AUTOSAR XML (schema 00045)
package /Fcu
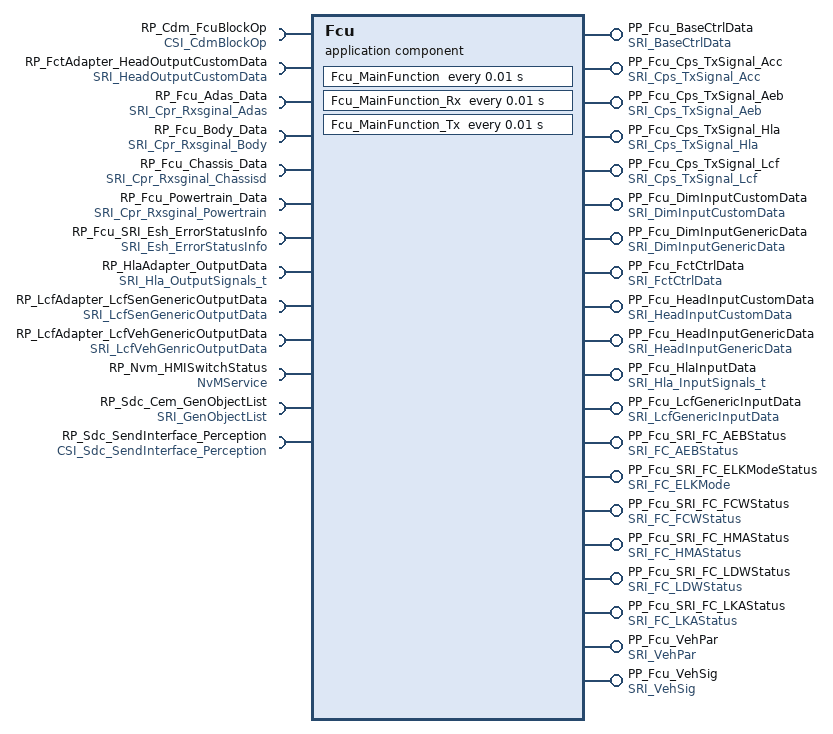
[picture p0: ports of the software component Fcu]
  application sw component type Fcu  # Functional Control Unit/Functional Conversion Unit
    20 x provide port:
      PP_Fcu_BaseCtrlData: provided-interface=SRI_BaseCtrlData
      PP_Fcu_Cps_TxSignal_Acc: provided-interface=SRI_Cps_TxSignal_Acc
      PP_Fcu_Cps_TxSignal_Aeb: provided-interface=SRI_Cps_TxSignal_Aeb
      PP_Fcu_Cps_TxSignal_Hla: provided-interface=SRI_Cps_TxSignal_Hla
      PP_Fcu_Cps_TxSignal_Lcf: provided-interface=SRI_Cps_TxSignal_Lcf
      PP_Fcu_DimInputCustomData: provided-interface=SRI_DimInputCustomData
      PP_Fcu_DimInputGenericData: provided-interface=SRI_DimInputGenericData
      PP_Fcu_FctCtrlData: provided-interface=SRI_FctCtrlData
      PP_Fcu_HeadInputCustomData: provided-interface=SRI_HeadInputCustomData
      PP_Fcu_HeadInputGenericData: provided-interface=SRI_HeadInputGenericData
      PP_Fcu_HlaInputData: provided-interface=SRI_Hla_InputSignals_t
      PP_Fcu_LcfGenericInputData: provided-interface=SRI_LcfGenericInputData
      PP_Fcu_SRI_FC_AEBStatus: provided-interface=SRI_FC_AEBStatus
      PP_Fcu_SRI_FC_ELKModeStatus: provided-interface=SRI_FC_ELKMode
      PP_Fcu_SRI_FC_FCWStatus: provided-interface=SRI_FC_FCWStatus
      PP_Fcu_SRI_FC_HMAStatus: provided-interface=SRI_FC_HMAStatus
      PP_Fcu_SRI_FC_LDWStatus: provided-interface=SRI_FC_LDWStatus
      PP_Fcu_SRI_FC_LKAStatus: provided-interface=SRI_FC_LKAStatus
      PP_Fcu_VehPar: provided-interface=SRI_VehPar
      PP_Fcu_VehSig: provided-interface=SRI_VehSig
    13 x require port:
      RP_Cdm_FcuBlockOp: required-interface=CSI_CdmBlockOp
      RP_FctAdapter_HeadOutputCustomData: required-interface=SRI_HeadOutputCustomData
      RP_Fcu_Adas_Data: required-interface=SRI_Cpr_Rxsginal_Adas
      RP_Fcu_Body_Data: required-interface=SRI_Cpr_Rxsginal_Body
      RP_Fcu_Chassis_Data: required-interface=SRI_Cpr_Rxsginal_Chassisd
      RP_Fcu_Powertrain_Data: required-interface=SRI_Cpr_Rxsginal_Powertrain
      RP_Fcu_SRI_Esh_ErrorStatusInfo: required-interface=SRI_Esh_ErrorStatusInfo
      RP_HlaAdapter_OutputData: required-interface=SRI_Hla_OutputSignals_t
      RP_LcfAdapter_LcfSenGenericOutputData: required-interface=SRI_LcfSenGenericOutputData
      RP_LcfAdapter_LcfVehGenericOutputData: required-interface=SRI_LcfVehGenricOutputData
      RP_Nvm_HMISwitchStatus: required-interface=NvMService
      RP_Sdc_Cem_GenObjectList: required-interface=SRI_GenObjectList
      RP_Sdc_SendInterface_Perception: required-interface=CSI_Sdc_SendInterface_Perception
    behavior Fcu_IB: handle-termination-and-restart=NO-SUPPORT
      init event InitEvent_Fcu_InitFunction: start-on-event=Fcu_InitFunction
      timing event TimingEvent_Fcu_MainFunction: start-on-event=Fcu_MainFunction, period=0.01
      timing event TimingEvent_Fcu_MainFunction_Rx: start-on-event=Fcu_MainFunction_Rx, period=0.01
      timing event TimingEvent_Fcu_MainFunction_Tx: start-on-event=Fcu_MainFunction_Tx, period=0.01
      4 x runnable:
        Fcu_InitFunction
          data-receive-point-by-arguments:
            4 x access:
              drparg_GenObjectList: accessed-variable=RP_Sdc_Cem_GenObjectList.GenObjectList
              drparg_HeadOutputCustomData: accessed-variable=RP_FctAdapter_HeadOutputCustomData.HeadOutputCustomData
              drparg_LcfSenGenericOutputDa: accessed-variable=RP_LcfAdapter_LcfSenGenericOutputData.LcfSenGenericOutputData
              drparg_LcfVehGenericOutputDa: accessed-variable=RP_LcfAdapter_LcfVehGenericOutputData.LcfVehGenricOutputData
          data-send-points:
            9 x access:
              dsp_BaseCtrlData: accessed-variable=PP_Fcu_BaseCtrlData.BaseCtrlData
              dsp_DimInputCustomData: accessed-variable=PP_Fcu_DimInputCustomData.DimInputCustomData
              dsp_DimInputGenericData: accessed-variable=PP_Fcu_DimInputGenericData.DimInputGenericData
              dsp_FctCtrlData: accessed-variable=PP_Fcu_FctCtrlData.FctCtrlData
              dsp_HeadInputCustomData: accessed-variable=PP_Fcu_HeadInputCustomData.HeadInputCustomData
              dsp_HeadInputGenericData: accessed-variable=PP_Fcu_HeadInputGenericData.HeadInputGenericData
              dsp_LcfGenericInputData: accessed-variable=PP_Fcu_LcfGenericInputData.LcfGenericInputData
              dsp_VehPar: accessed-variable=PP_Fcu_VehPar.VehPar
              dsp_VehSig: accessed-variable=PP_Fcu_VehSig.VehSig
        Fcu_MainFunction
          data-receive-point-by-arguments:
            258 x access:
              drparg_ACCMode: accessed-variable=RP_Fcu_Adas_Data.ACCMode
              drparg_ACCMode_Status: accessed-variable=RP_Fcu_Adas_Data.ACCMode_Status
              drparg_ACC_HostLaneLeftStatus: accessed-variable=RP_Fcu_Body_Data.ACC_HostLaneLeftStatus
              drparg_ACC_HostLaneRightStat: accessed-variable=RP_Fcu_Body_Data.ACC_HostLaneRightStatus
              drparg_ACC_IACCHWAMode: accessed-variable=RP_Fcu_Body_Data.AccIaccHWAMode
              drparg_AccIaccHWAMode_Status: accessed-variable=RP_Fcu_Body_Data.AccIaccHWAMode_Status
              drparg_AdsUDLCStatus: accessed-variable=RP_Fcu_Chassis_Data.AdsUDLCStatus
              drparg_AdsUDLCStatus_Status: accessed-variable=RP_Fcu_Chassis_Data.AdsUDLCStatus_Status
              drparg_BCM_BrakeLampError: accessed-variable=RP_Fcu_Body_Data.BCM_BrakeLampError
              drparg_BCM_BrakeLampError_St: accessed-variable=RP_Fcu_Body_Data.BCM_BrakeLampError_Status
              drparg_BCM_TurnLightSwitchSt: accessed-variable=RP_Fcu_Body_Data.BCM_TurnLightSwitchSts_Status
              drparg_BCM_TurnLightSwitchSts: accessed-variable=RP_Fcu_Body_Data.BCM_TurnLightSwitchSts
              drparg_BcmAutHeadLiSts: accessed-variable=RP_Fcu_Body_Data.BcmAutHeadLiSts
              drparg_BcmAutHeadLiSts_Status: accessed-variable=RP_Fcu_Body_Data.BcmAutHeadLiSts_Status
              drparg_BcmDrvrDoorSts: accessed-variable=RP_Fcu_Body_Data.BcmDrvrDoorSts
              drparg_BcmDrvrDoorSts_Status: accessed-variable=RP_Fcu_Body_Data.BcmDrvrDoorSts_Status
              drparg_BcmEmgyLiSts: accessed-variable=RP_Fcu_Body_Data.BcmEmgyLiSts
              drparg_BcmEmgyLiSts_Status: accessed-variable=RP_Fcu_Body_Data.BcmEmgyLiSts_Status
              drparg_BcmFrntFogLmpSts: accessed-variable=RP_Fcu_Body_Data.BcmFrntFogLmpSts
              drparg_BcmFrntFogLmpSts_Stat: accessed-variable=RP_Fcu_Body_Data.BcmFrntFogLmpSts_Status
              drparg_BcmFrntWiperSts: accessed-variable=RP_Fcu_Body_Data.BcmFrntWiperSts
              drparg_BcmFrntWiperSts_Status: accessed-variable=RP_Fcu_Body_Data.BcmFrntWiperSts_Status
              drparg_BcmHiBeamSts: accessed-variable=RP_Fcu_Body_Data.BcmHiBeamSts
              drparg_BcmHiBeamSts_Status: accessed-variable=RP_Fcu_Body_Data.BcmHiBeamSts_Status
              drparg_BcmLeReDoorSts: accessed-variable=RP_Fcu_Body_Data.BcmLeReDoorSts
              drparg_BcmLeReDoorSts_Status: accessed-variable=RP_Fcu_Body_Data.BcmLeReDoorSts_Status
              drparg_BcmLoBeamSts: accessed-variable=RP_Fcu_Body_Data.BcmLoBeamSts
              drparg_BcmLoBeamSts_Status: accessed-variable=RP_Fcu_Body_Data.BcmLoBeamSts_Status
              drparg_BcmPassDoorSts: accessed-variable=RP_Fcu_Body_Data.BcmPassDoorSts
              drparg_BcmPassDoorSts_Status: accessed-variable=RP_Fcu_Body_Data.BcmPassDoorSts_Status
              drparg_BcmReFoglmpSts: accessed-variable=RP_Fcu_Body_Data.BcmReFoglmpSts
              drparg_BcmReFoglmpSts_Status: accessed-variable=RP_Fcu_Body_Data.BcmReFoglmpSts_Status
              drparg_BcmRiReDoorSts: accessed-variable=RP_Fcu_Body_Data.BcmRiReDoorSts
              drparg_BcmRiReDoorSts_Status: accessed-variable=RP_Fcu_Body_Data.BcmRiReDoorSts_Status
              drparg_BcmTurnIndcrLe: accessed-variable=RP_Fcu_Body_Data.BcmTurnIndcrLe
              drparg_BcmTurnIndcrLe_Status: accessed-variable=RP_Fcu_Body_Data.BcmTurnIndcrLe_Status
              drparg_BcmTurnIndcrRi: accessed-variable=RP_Fcu_Body_Data.BcmTurnIndcrRi
              drparg_BcmTurnIndcrRi_Status: accessed-variable=RP_Fcu_Body_Data.BcmTurnIndcrRi_Status
              drparg_BrakePressureSimulato: accessed-variable=RP_Fcu_Chassis_Data.BrakePressureSimulator_Status
              drparg_BrakePressureSimulator: accessed-variable=RP_Fcu_Chassis_Data.BrakePressureSimulator
              drparg_DE_Esh_ErrorStatusInfo: accessed-variable=RP_Fcu_SRI_Esh_ErrorStatusInfo.DE_Esh_ErrorStatusInfo
              drparg_EPS_APA_EpasFAILED: accessed-variable=RP_Fcu_Chassis_Data.EPS_APA_EpasFAILED
              drparg_EPS_APA_EpasFAILED_St: accessed-variable=RP_Fcu_Chassis_Data.EPS_APA_EpasFAILED_Status
              drparg_EPS_ActualMotorTorq: accessed-variable=RP_Fcu_Chassis_Data.EPS_ActualMotorTorq
              drparg_EPS_ActualMotorTorq_S: accessed-variable=RP_Fcu_Chassis_Data.EPS_ActualMotorTorq_Status
              drparg_EPS_ActualTorsionBarT: accessed-variable=RP_Fcu_Chassis_Data.EPS_ActualTorsionBarTorq
              drparg_EPS_ActualTorsionBarT0: accessed-variable=RP_Fcu_Chassis_Data.EPS_ActualTorsionBarTorq_Status
              drparg_EPS_MeasuredTorsionBa: accessed-variable=RP_Fcu_Chassis_Data.EPS_MeasuredTorsionBarTorqValid
              drparg_EPS_Pinionang_Vali: accessed-variable=RP_Fcu_Chassis_Data.EPS_Pinionang_Valid
              drparg_EPS_fault_state: accessed-variable=RP_Fcu_Chassis_Data.EPS_fault_state
              drparg_EPS_fault_state_Status: accessed-variable=RP_Fcu_Chassis_Data.EPS_fault_state_Status
              drparg_ESP_LatAccelValid: accessed-variable=RP_Fcu_Chassis_Data.ESP_LatAccelValid
              drparg_ESP_LongAccelValid: accessed-variable=RP_Fcu_Chassis_Data.ESP_LongAccelValid
              drparg_ESP_YawRateValid: accessed-variable=RP_Fcu_Chassis_Data.ESP_YawRateValid
              drparg_EpsConcussAvailabilit: accessed-variable=RP_Fcu_Chassis_Data.EpsConcussAvailabilityStatus
              drparg_EpsConcussAvailabilit0: accessed-variable=RP_Fcu_Chassis_Data.EpsConcussAvailabilityStatus_Status
              drparg_EpsFaild: accessed-variable=RP_Fcu_Chassis_Data.EpsFaild
              drparg_EpsFaild_Status: accessed-variable=RP_Fcu_Chassis_Data.EpsFaild_Status
              drparg_EpsIACCabortreason: accessed-variable=RP_Fcu_Chassis_Data.EpsIACCabortreason
              drparg_EpsIACCabortreason_St: accessed-variable=RP_Fcu_Chassis_Data.EpsIACCabortreason_Status
              drparg_EpsLatCtrlActive: accessed-variable=RP_Fcu_Chassis_Data.EpsLatCtrlActive
              drparg_EpsLatCtrlActive_Stat: accessed-variable=RP_Fcu_Chassis_Data.EpsLatCtrlActive_Status
              drparg_EpsLatCtrlAvailabilit: accessed-variable=RP_Fcu_Chassis_Data.EpsLatCtrlAvailabilityStatus
              drparg_EpsLatCtrlAvailabilit0: accessed-variable=RP_Fcu_Chassis_Data.EpsLatCtrlAvailabilityStatus_Status
              drparg_EpsMeasuredTorsionBar: accessed-variable=RP_Fcu_Chassis_Data.EpsMeasuredTorsionBarTorque
              drparg_EpsMeasuredTorsionBar0: accessed-variable=RP_Fcu_Chassis_Data.EpsMeasuredTorsionBarTorq_Status
              drparg_EpsMeasuredTorsionBar1: accessed-variable=RP_Fcu_Chassis_Data.EpsMeasuredTorsionBarTorque_Status
              drparg_EpsPinionang: accessed-variable=RP_Fcu_Chassis_Data.EpsPinionang
              drparg_EpsPinionang_Status: accessed-variable=RP_Fcu_Chassis_Data.EpsPinionang_Status
              drparg_EpsSasCalSts: accessed-variable=RP_Fcu_Chassis_Data.EpsSasCalSts
              drparg_EpsSasCalSts_Status: accessed-variable=RP_Fcu_Chassis_Data.EpsSasCalSts_Status
              drparg_EpsSasSteerAg: accessed-variable=RP_Fcu_Chassis_Data.EpsSasSteerAg
              drparg_EpsSasSteerAgVld: accessed-variable=RP_Fcu_Chassis_Data.EpsSasSteerAgVld
              drparg_EpsSasSteerAg_Status: accessed-variable=RP_Fcu_Chassis_Data.EpsSasSteerAg_Status
              drparg_EpsSteerAgRate: accessed-variable=RP_Fcu_Chassis_Data.EpsSteerAgRate
              drparg_EpsSteerAgRate_Status: accessed-variable=RP_Fcu_Chassis_Data.EpsSteerAgRate_Status
              drparg_EpsSteerAgSensFilr: accessed-variable=RP_Fcu_Chassis_Data.EpsSteerAgSensFilr
              drparg_EpsSteerAgSensFilr_St: accessed-variable=RP_Fcu_Chassis_Data.EpsSteerAgSensFilr_Status
              drparg_EspABAactive: accessed-variable=RP_Fcu_Chassis_Data.EspABAactive
              drparg_EspABAactive_Status: accessed-variable=RP_Fcu_Chassis_Data.EspABAactive_Status
              drparg_EspABAavailable: accessed-variable=RP_Fcu_Chassis_Data.EspABAavailable
              drparg_EspABAavailable_Status: accessed-variable=RP_Fcu_Chassis_Data.EspABAavailable_Status
              drparg_EspAEBAvailable: accessed-variable=RP_Fcu_Chassis_Data.EspAEBAvailable
              drparg_EspAEBAvailable_Status: accessed-variable=RP_Fcu_Chassis_Data.EspAEBAvailable_Status
              drparg_EspAEBdecActive: accessed-variable=RP_Fcu_Chassis_Data.EspAEBdecActive
              drparg_EspAEBdecActive_Status: accessed-variable=RP_Fcu_Chassis_Data.EspAEBdecActive_Status
              drparg_EspAWBactive: accessed-variable=RP_Fcu_Chassis_Data.EspAWBactive
              drparg_EspAWBactive_Status: accessed-variable=RP_Fcu_Chassis_Data.EspAWBactive_Status
              drparg_EspAWBavailable: accessed-variable=RP_Fcu_Chassis_Data.EspAWBavailable
              drparg_EspAWBavailable_Status: accessed-variable=RP_Fcu_Chassis_Data.EspAWBavailable_Status
              drparg_EspAbsActv: accessed-variable=RP_Fcu_Chassis_Data.EspAbsActv
              drparg_EspAbsActv_Status: accessed-variable=RP_Fcu_Chassis_Data.EspAbsActv_Status
              drparg_EspAbsFailr: accessed-variable=RP_Fcu_Chassis_Data.EspAbsFailr
              drparg_EspAbsFailr_Status: accessed-variable=RP_Fcu_Chassis_Data.EspAbsFailr_Status
              drparg_EspActvSts: accessed-variable=RP_Fcu_Chassis_Data.EspActvSts
              drparg_EspActvSts_Status: accessed-variable=RP_Fcu_Chassis_Data.EspActvSts_Status
              drparg_EspEbdFailr: accessed-variable=RP_Fcu_Chassis_Data.EspEbdFailr
              drparg_EspEbdFailr_Status: accessed-variable=RP_Fcu_Chassis_Data.EspEbdFailr_Status
              drparg_EspLatAccel: accessed-variable=RP_Fcu_Chassis_Data.EspLatAccel
              drparg_EspLatAccel_Status: accessed-variable=RP_Fcu_Chassis_Data.EspLatAccel_Status
              drparg_EspLongAccel: accessed-variable=RP_Fcu_Chassis_Data.EspLongAccel
              drparg_EspLongAccel_Status: accessed-variable=RP_Fcu_Chassis_Data.EspLongAccel_Status
              drparg_EspPrefillActive: accessed-variable=RP_Fcu_Chassis_Data.EspPrefillActive
              drparg_EspPrefillActive_Stat: accessed-variable=RP_Fcu_Chassis_Data.EspPrefillActive_Status
              drparg_EspPrefillAvailable: accessed-variable=RP_Fcu_Chassis_Data.EspPrefillAvailable
              drparg_EspPrefillAvailable_S: accessed-variable=RP_Fcu_Chassis_Data.EspPrefillAvailable_Status
              drparg_EspTcsActvSts: accessed-variable=RP_Fcu_Chassis_Data.EspTcsActvSts
              drparg_EspTcsActvSts_Status: accessed-variable=RP_Fcu_Chassis_Data.EspTcsActvSts_Status
              drparg_EspTcsFailr: accessed-variable=RP_Fcu_Chassis_Data.EspTcsFailr
              drparg_EspTcsFailr_Status: accessed-variable=RP_Fcu_Chassis_Data.EspTcsFailr_Status
              drparg_EspVdcActvSts: accessed-variable=RP_Fcu_Chassis_Data.EspVdcActvSts
              drparg_EspVdcActvSts_Status: accessed-variable=RP_Fcu_Chassis_Data.EspVdcActvSts_Status
              drparg_EspVehSpd: accessed-variable=RP_Fcu_Chassis_Data.EspVehSpd
              drparg_EspVehSpdVld: accessed-variable=RP_Fcu_Chassis_Data.EspVehSpdVld
              drparg_EspVehSpd_Status: accessed-variable=RP_Fcu_Chassis_Data.EspVehSpd_Status
              drparg_EspYawRate: accessed-variable=RP_Fcu_Chassis_Data.EspYawRate
              drparg_EspYawRate_Status: accessed-variable=RP_Fcu_Chassis_Data.EspYawRate_Status
              drparg_FR_RadarFailureStatus: accessed-variable=RP_Fcu_Adas_Data.FR_RadarFailureStatus
              drparg_FR_RadarFailureStatus0: accessed-variable=RP_Fcu_Adas_Data.FR_RadarFailureStatus_Status
              drparg_FRadarCalibrationStat: accessed-variable=RP_Fcu_Adas_Data.FRadarCalibrationStatus
              drparg_FRadarCalibrationStat0: accessed-variable=RP_Fcu_Adas_Data.FRadarCalibrationStatus_Status
              drparg_GenObjectList: accessed-variable=RP_Sdc_Cem_GenObjectList.GenObjectList
              drparg_HeadOutputCustomData: accessed-variable=RP_FctAdapter_HeadOutputCustomData.HeadOutputCustomData
              drparg_Hla_OutputSignals_t: accessed-variable=RP_HlaAdapter_OutputData.Hla_OutputSignals_t
              drparg_IBCU_PFSBrakePressure: accessed-variable=RP_Fcu_Chassis_Data.IBCU_PFSBrakePressureValid
              drparg_IP_DISFail: accessed-variable=RP_Fcu_Body_Data.IP_DISFail
              drparg_IP_DISFail_Status: accessed-variable=RP_Fcu_Body_Data.IP_DISFail_Status
              drparg_IP_QDashACCFail: accessed-variable=RP_Fcu_Body_Data.IP_QDashACCFail
              drparg_IP_QDashACCFail_Status: accessed-variable=RP_Fcu_Body_Data.IP_QDashACCFail_Status
              drparg_IbBrkPedlStsGb: accessed-variable=RP_Fcu_Chassis_Data.IbBrkPedlStsGb
              drparg_IbBrkPedlStsGbVld: accessed-variable=RP_Fcu_Chassis_Data.IbBrkPedlStsGbVld
              drparg_IbBrkPedlStsGb_Status: accessed-variable=RP_Fcu_Chassis_Data.IbBrkPedlStsGb_Status
              drparg_IbBrkPedlTrvlDrvr: accessed-variable=RP_Fcu_Chassis_Data.IbBrkPedlTrvlDrvr
              drparg_IbBrkPedlTrvlDrvrVld: accessed-variable=RP_Fcu_Chassis_Data.IbBrkPedlTrvlDrvrVld
              drparg_LcfSenGenericOutputDa: accessed-variable=RP_LcfAdapter_LcfSenGenericOutputData.LcfSenGenericOutputData
              drparg_LcfVehGenericOutputDa: accessed-variable=RP_LcfAdapter_LcfVehGenericOutputData.LcfVehGenricOutputData
              drparg_PlungerBrakePressure: accessed-variable=RP_Fcu_Chassis_Data.PlungerBrakePressure
              drparg_PlungerBrakePressure_: accessed-variable=RP_Fcu_Chassis_Data.PlungerBrakePressure_Status
              drparg_RadarObj1_Dx: accessed-variable=RP_Fcu_Adas_Data.RadarObj1_Dx
              drparg_RadarObj1_Dx_Status: accessed-variable=RP_Fcu_Adas_Data.RadarObj1_Dx_Status
              drparg_RadarObj1_Dy: accessed-variable=RP_Fcu_Adas_Data.RadarObj1_Dy
              drparg_RadarObj1_Dy_Status: accessed-variable=RP_Fcu_Adas_Data.RadarObj1_Dy_Status
              drparg_RadarObj1_ExistProb: accessed-variable=RP_Fcu_Adas_Data.RadarObj1_ExistProb
              drparg_RadarObj1_ExistProb_S: accessed-variable=RP_Fcu_Adas_Data.RadarObj1_ExistProb_Status
              drparg_RadarObj1_Length: accessed-variable=RP_Fcu_Adas_Data.RadarObj1_Length
              drparg_RadarObj1_Length_Stat: accessed-variable=RP_Fcu_Adas_Data.RadarObj1_Length_Status
              drparg_RadarObj1_Location: accessed-variable=RP_Fcu_Adas_Data.RadarObj1_Location
              drparg_RadarObj1_Location_St: accessed-variable=RP_Fcu_Adas_Data.RadarObj1_Location_Status
              drparg_RadarObj1_Measured: accessed-variable=RP_Fcu_Adas_Data.RadarObj1_Measured
              drparg_RadarObj1_Measured_St: accessed-variable=RP_Fcu_Adas_Data.RadarObj1_Measured_Status
              drparg_RadarObj1_RelAx: accessed-variable=RP_Fcu_Adas_Data.RadarObj1_RelAx
              drparg_RadarObj1_RelAx_Status: accessed-variable=RP_Fcu_Adas_Data.RadarObj1_RelAx_Status
              drparg_RadarObj1_RelVx: accessed-variable=RP_Fcu_Adas_Data.RadarObj1_RelVx
              drparg_RadarObj1_RelVx_Status: accessed-variable=RP_Fcu_Adas_Data.RadarObj1_RelVx_Status
              drparg_RadarObj1_RelVy: accessed-variable=RP_Fcu_Adas_Data.RadarObj1_RelVy
              drparg_RadarObj1_RelVy_Status: accessed-variable=RP_Fcu_Adas_Data.RadarObj1_RelVy_Status
              drparg_RadarObj1_Width: accessed-variable=RP_Fcu_Adas_Data.RadarObj1_Width
              drparg_RadarObj1_Width_Status: accessed-variable=RP_Fcu_Adas_Data.RadarObj1_Width_Status
              drparg_RadarObj2_Dx: accessed-variable=RP_Fcu_Adas_Data.RadarObj2_Dx
              drparg_RadarObj2_Dx_Status: accessed-variable=RP_Fcu_Adas_Data.RadarObj2_Dx_Status
              drparg_RadarObj2_Dy: accessed-variable=RP_Fcu_Adas_Data.RadarObj2_Dy
              drparg_RadarObj2_Dy_Status: accessed-variable=RP_Fcu_Adas_Data.RadarObj2_Dy_Status
              drparg_RadarObj2_ExistProb: accessed-variable=RP_Fcu_Adas_Data.RadarObj2_ExistProb
              drparg_RadarObj2_ExistProb_S: accessed-variable=RP_Fcu_Adas_Data.RadarObj2_ExistProb_Status
              drparg_RadarObj2_Length: accessed-variable=RP_Fcu_Adas_Data.RadarObj2_Length
              drparg_RadarObj2_Length_Stat: accessed-variable=RP_Fcu_Adas_Data.RadarObj2_Length_Status
              drparg_RadarObj2_Location: accessed-variable=RP_Fcu_Adas_Data.RadarObj2_Location
              drparg_RadarObj2_Location_St: accessed-variable=RP_Fcu_Adas_Data.RadarObj2_Location_Status
              drparg_RadarObj2_Measured: accessed-variable=RP_Fcu_Adas_Data.RadarObj2_Measured
              drparg_RadarObj2_Measured_St: accessed-variable=RP_Fcu_Adas_Data.RadarObj2_Measured_Status
              drparg_RadarObj2_RelAx: accessed-variable=RP_Fcu_Adas_Data.RadarObj2_RelAx
              drparg_RadarObj2_RelAx_Status: accessed-variable=RP_Fcu_Adas_Data.RadarObj2_RelAx_Status
              drparg_RadarObj2_RelVx: accessed-variable=RP_Fcu_Adas_Data.RadarObj2_RelVx
              drparg_RadarObj2_RelVx_Status: accessed-variable=RP_Fcu_Adas_Data.RadarObj2_RelVx_Status
              drparg_RadarObj2_RelVy: accessed-variable=RP_Fcu_Adas_Data.RadarObj2_RelVy
              drparg_RadarObj2_RelVy_Status: accessed-variable=RP_Fcu_Adas_Data.RadarObj2_RelVy_Status
              drparg_RadarObj2_Width: accessed-variable=RP_Fcu_Adas_Data.RadarObj2_Width
              drparg_RadarObj2_Width_Status: accessed-variable=RP_Fcu_Adas_Data.RadarObj2_Width_Status
              drparg_RadarObj3_Dx: accessed-variable=RP_Fcu_Adas_Data.RadarObj3_Dx
              drparg_RadarObj3_Dx_Status: accessed-variable=RP_Fcu_Adas_Data.RadarObj3_Dx_Status
              drparg_RadarObj3_Dy: accessed-variable=RP_Fcu_Adas_Data.RadarObj3_Dy
              drparg_RadarObj3_Dy_Status: accessed-variable=RP_Fcu_Adas_Data.RadarObj3_Dy_Status
              drparg_RadarObj3_ExistProb: accessed-variable=RP_Fcu_Adas_Data.RadarObj3_ExistProb
              drparg_RadarObj3_ExistProb_S: accessed-variable=RP_Fcu_Adas_Data.RadarObj3_ExistProb_Status
              drparg_RadarObj3_Length: accessed-variable=RP_Fcu_Adas_Data.RadarObj3_Length
              drparg_RadarObj3_Length_Stat: accessed-variable=RP_Fcu_Adas_Data.RadarObj3_Length_Status
              drparg_RadarObj3_Location: accessed-variable=RP_Fcu_Adas_Data.RadarObj3_Location
              drparg_RadarObj3_Location_St: accessed-variable=RP_Fcu_Adas_Data.RadarObj3_Location_Status
              drparg_RadarObj3_Measured: accessed-variable=RP_Fcu_Adas_Data.RadarObj3_Measured
              drparg_RadarObj3_Measured_St: accessed-variable=RP_Fcu_Adas_Data.RadarObj3_Measured_Status
              drparg_RadarObj3_RelAx: accessed-variable=RP_Fcu_Adas_Data.RadarObj3_RelAx
              drparg_RadarObj3_RelAx_Status: accessed-variable=RP_Fcu_Adas_Data.RadarObj3_RelAx_Status
              drparg_RadarObj3_RelVx: accessed-variable=RP_Fcu_Adas_Data.RadarObj3_RelVx
              drparg_RadarObj3_RelVx_Status: accessed-variable=RP_Fcu_Adas_Data.RadarObj3_RelVx_Status
              drparg_RadarObj3_RelVy: accessed-variable=RP_Fcu_Adas_Data.RadarObj3_RelVy
              drparg_RadarObj3_RelVy_Status: accessed-variable=RP_Fcu_Adas_Data.RadarObj3_RelVy_Status
              drparg_RadarObj3_Width: accessed-variable=RP_Fcu_Adas_Data.RadarObj3_Width
              drparg_RadarObj3_Width_Status: accessed-variable=RP_Fcu_Adas_Data.RadarObj3_Width_Status
              drparg_RadarObj4_Dx: accessed-variable=RP_Fcu_Adas_Data.RadarObj4_Dx
              drparg_RadarObj4_Dx_Status: accessed-variable=RP_Fcu_Adas_Data.RadarObj4_Dx_Status
              drparg_RadarObj4_Dy: accessed-variable=RP_Fcu_Adas_Data.RadarObj4_Dy
              drparg_RadarObj4_Dy_Status: accessed-variable=RP_Fcu_Adas_Data.RadarObj4_Dy_Status
              drparg_RadarObj4_ExistProb: accessed-variable=RP_Fcu_Adas_Data.RadarObj4_ExistProb
              drparg_RadarObj4_ExistProb_S: accessed-variable=RP_Fcu_Adas_Data.RadarObj4_ExistProb_Status
              drparg_RadarObj4_Length: accessed-variable=RP_Fcu_Adas_Data.RadarObj4_Length
              drparg_RadarObj4_Length_Stat: accessed-variable=RP_Fcu_Adas_Data.RadarObj4_Length_Status
              drparg_RadarObj4_Location: accessed-variable=RP_Fcu_Adas_Data.RadarObj4_Location
              drparg_RadarObj4_Location_St: accessed-variable=RP_Fcu_Adas_Data.RadarObj4_Location_Status
              drparg_RadarObj4_Measured: accessed-variable=RP_Fcu_Adas_Data.RadarObj4_Measured
              drparg_RadarObj4_Measured_St: accessed-variable=RP_Fcu_Adas_Data.RadarObj4_Measured_Status
              drparg_RadarObj4_RelAx: accessed-variable=RP_Fcu_Adas_Data.RadarObj4_RelAx
              drparg_RadarObj4_RelAx_Status: accessed-variable=RP_Fcu_Adas_Data.RadarObj4_RelAx_Status
              drparg_RadarObj4_RelVx: accessed-variable=RP_Fcu_Adas_Data.RadarObj4_RelVx
              drparg_RadarObj4_RelVx_Status: accessed-variable=RP_Fcu_Adas_Data.RadarObj4_RelVx_Status
              drparg_RadarObj4_RelVy: accessed-variable=RP_Fcu_Adas_Data.RadarObj4_RelVy
              drparg_RadarObj4_RelVy_Status: accessed-variable=RP_Fcu_Adas_Data.RadarObj4_RelVy_Status
              drparg_RadarObj4_Width: accessed-variable=RP_Fcu_Adas_Data.RadarObj4_Width
              drparg_RadarObj4_Width_Status: accessed-variable=RP_Fcu_Adas_Data.RadarObj4_Width_Status
              drparg_SrsDrvrBucSwtSts: accessed-variable=RP_Fcu_Body_Data.SrsDrvrBucSwtSts
              drparg_SrsDrvrBucSwtSts_Stat: accessed-variable=RP_Fcu_Body_Data.SrsDrvrBucSwtSts_Status
              drparg_SrsPassBucSwtSts: accessed-variable=RP_Fcu_Body_Data.SrsPassBucSwtSts
              drparg_SrsPassBucSwtSts_Stat: accessed-variable=RP_Fcu_Body_Data.SrsPassBucSwtSts_Status
              drparg_TmsFrntBlowMod: accessed-variable=RP_Fcu_Body_Data.TmsFrntBlowMod
              drparg_TmsFrntBlowMod_Status: accessed-variable=RP_Fcu_Body_Data.TmsFrntBlowMod_Status
              drparg_VcuAccrPedlPosn: accessed-variable=RP_Fcu_Chassis_Data.VcuAccrPedlPosn
              drparg_VcuAccrPedlPosnVld: accessed-variable=RP_Fcu_Chassis_Data.VcuAccrPedlPosnVld
              drparg_VcuAccrPedlPosn_Status: accessed-variable=RP_Fcu_Chassis_Data.VcuAccrPedlPosn_Status
              drparg_VcuGearPosn: accessed-variable=RP_Fcu_Chassis_Data.VcuGearPosn
              drparg_VcuGearPosn_Status: accessed-variable=RP_Fcu_Chassis_Data.VcuGearPosn_Status
              drparg_VcuVehGearPosnVld: accessed-variable=RP_Fcu_Chassis_Data.VcuVehGearPosnVld
              drparg_WhlSpdFrntLePls: accessed-variable=RP_Fcu_Powertrain_Data.WhlSpdFrntLePls
              drparg_WhlSpdFrntLePls_Status: accessed-variable=RP_Fcu_Powertrain_Data.WhlSpdFrntLePls_Status
              drparg_WhlSpdFrntRiPls: accessed-variable=RP_Fcu_Powertrain_Data.WhlSpdFrntRiPls
              drparg_WhlSpdFrntRiPls_Status: accessed-variable=RP_Fcu_Powertrain_Data.WhlSpdFrntRiPls_Status
              drparg_WhlSpdLeFrntData: accessed-variable=RP_Fcu_Powertrain_Data.WhlSpdLeFrntData
              drparg_WhlSpdLeFrntDataVld: accessed-variable=RP_Fcu_Powertrain_Data.WhlSpdLeFrntDataVld
              drparg_WhlSpdLeFrntData_Stat: accessed-variable=RP_Fcu_Powertrain_Data.WhlSpdLeFrntData_Status
              drparg_WhlSpdLeFrntDir: accessed-variable=RP_Fcu_Powertrain_Data.WhlSpdLeFrntDir
              drparg_WhlSpdLeFrntDir_Status: accessed-variable=RP_Fcu_Powertrain_Data.WhlSpdLeFrntDir_Status
              drparg_WhlSpdLeReData: accessed-variable=RP_Fcu_Powertrain_Data.WhlSpdLeReData
              drparg_WhlSpdLeReDataVld: accessed-variable=RP_Fcu_Powertrain_Data.WhlSpdLeReDataVld
              drparg_WhlSpdLeReData_Status: accessed-variable=RP_Fcu_Powertrain_Data.WhlSpdLeReData_Status
              drparg_WhlSpdLeReDir: accessed-variable=RP_Fcu_Powertrain_Data.WhlSpdLeReDir
              drparg_WhlSpdLeReDir_Status: accessed-variable=RP_Fcu_Powertrain_Data.WhlSpdLeReDir_Status
              drparg_WhlSpdReLePls: accessed-variable=RP_Fcu_Powertrain_Data.WhlSpdReLePls
              drparg_WhlSpdReLePls_Status: accessed-variable=RP_Fcu_Powertrain_Data.WhlSpdReLePls_Status
              drparg_WhlSpdReRiPls: accessed-variable=RP_Fcu_Powertrain_Data.WhlSpdReRiPls
              drparg_WhlSpdReRiPls_Status: accessed-variable=RP_Fcu_Powertrain_Data.WhlSpdReRiPls_Status
              drparg_WhlSpdRiFrntData: accessed-variable=RP_Fcu_Powertrain_Data.WhlSpdRiFrntData
              drparg_WhlSpdRiFrntDataVld: accessed-variable=RP_Fcu_Powertrain_Data.WhlSpdRiFrntDataVld
              drparg_WhlSpdRiFrntData_Stat: accessed-variable=RP_Fcu_Powertrain_Data.WhlSpdRiFrntData_Status
              drparg_WhlSpdRiFrntDir: accessed-variable=RP_Fcu_Powertrain_Data.WhlSpdRiFrntDir
              drparg_WhlSpdRiFrntDir_Status: accessed-variable=RP_Fcu_Powertrain_Data.WhlSpdRiFrntDir_Status
              drparg_WhlSpdRiReData: accessed-variable=RP_Fcu_Powertrain_Data.WhlSpdRiReData
              drparg_WhlSpdRiReDataVld: accessed-variable=RP_Fcu_Powertrain_Data.WhlSpdRiReDataVld
              drparg_WhlSpdRiReData_Status: accessed-variable=RP_Fcu_Powertrain_Data.WhlSpdRiReData_Status
              drparg_WhlSpdRiReDir: accessed-variable=RP_Fcu_Powertrain_Data.WhlSpdRiReDir
              drparg_WhlSpdRiReDir_Status: accessed-variable=RP_Fcu_Powertrain_Data.WhlSpdRiReDir_Status
          data-send-points:
            73 x access:
              dsp_BaseCtrlData: accessed-variable=PP_Fcu_BaseCtrlData.BaseCtrlData
              dsp_Cps_SignalPhyData_ACC_Ho: accessed-variable=PP_Fcu_Cps_TxSignal_Lcf.Cps_SignalPhyData_ACC_HostLaneLeftStatus
              dsp_Cps_SignalPhyData_ACC_Ho0: accessed-variable=PP_Fcu_Cps_TxSignal_Lcf.Cps_SignalPhyData_ACC_HostLaneRightStatus
              dsp_Cps_SignalPhyData_ACC_La: accessed-variable=PP_Fcu_Cps_TxSignal_Lcf.Cps_SignalPhyData_ACC_LatAngReq
              dsp_Cps_SignalPhyData_ACC_La0: accessed-variable=PP_Fcu_Cps_TxSignal_Lcf.Cps_SignalPhyData_ACC_LatAngReqActive
              dsp_Cps_SignalPhyData_FC_ABA: accessed-variable=PP_Fcu_Cps_TxSignal_Aeb.Cps_SignalPhyData_FC_ABAlevel
              dsp_Cps_SignalPhyData_FC_ABA0: accessed-variable=PP_Fcu_Cps_TxSignal_Aeb.Cps_SignalPhyData_FC_ABAActive
              dsp_Cps_SignalPhyData_FC_AEB: accessed-variable=PP_Fcu_Cps_TxSignal_Aeb.Cps_SignalPhyData_FC_AEBActive
              dsp_Cps_SignalPhyData_FC_AEB0: accessed-variable=PP_Fcu_Cps_TxSignal_Aeb.Cps_SignalPhyData_FC_AEBCtrlType
              dsp_Cps_SignalPhyData_FC_AEB1: accessed-variable=PP_Fcu_Cps_TxSignal_Aeb.Cps_SignalPhyData_FC_AEBEnable
              dsp_Cps_SignalPhyData_FC_AEB10: accessed-variable=PP_Fcu_Cps_TxSignal_Aeb.Cps_SignalPhyData_FC_AEBVehilceHoldReq
              dsp_Cps_SignalPhyData_FC_AEB11: accessed-variable=PP_Fcu_Cps_TxSignal_Aeb.Cps_SignalPhyData_FC_AEBStatus
              dsp_Cps_SignalPhyData_FC_AEB12: accessed-variable=PP_Fcu_Cps_TxSignal_Aeb.Cps_SignalPhyData_FC_AEBTargetAy
              dsp_Cps_SignalPhyData_FC_AEB13: accessed-variable=PP_Fcu_Cps_TxSignal_Aeb.Cps_SignalPhyData_FC_AEBTargetAx
              dsp_Cps_SignalPhyData_FC_AEB14: accessed-variable=PP_Fcu_Cps_TxSignal_Aeb.Cps_SignalPhyData_FC_AEBTargetProb
              dsp_Cps_SignalPhyData_FC_AEB15: accessed-variable=PP_Fcu_Cps_TxSignal_Aeb.Cps_SignalPhyData_FC_AEBTargetLatRelSpeed
              dsp_Cps_SignalPhyData_FC_AEB2: accessed-variable=PP_Fcu_Cps_TxSignal_Aeb.Cps_SignalPhyData_FC_AEBTargetDeceleration
              dsp_Cps_SignalPhyData_FC_AEB3: accessed-variable=PP_Fcu_Cps_TxSignal_Aeb.Cps_SignalPhyData_FC_AEBTargetDetection
              dsp_Cps_SignalPhyData_FC_AEB4: accessed-variable=PP_Fcu_Cps_TxSignal_Aeb.Cps_SignalPhyData_FC_AEBTargetLatRange
              dsp_Cps_SignalPhyData_FC_AEB5: accessed-variable=PP_Fcu_Cps_TxSignal_Aeb.Cps_SignalPhyData_FC_AEBTargetLngRange
              dsp_Cps_SignalPhyData_FC_AEB6: accessed-variable=PP_Fcu_Cps_TxSignal_Aeb.Cps_SignalPhyData_FC_AEBTargetRelSpeed
              dsp_Cps_SignalPhyData_FC_AEB7: accessed-variable=PP_Fcu_Cps_TxSignal_Aeb.Cps_SignalPhyData_FC_AEBTargetType
              dsp_Cps_SignalPhyData_FC_AEB8: accessed-variable=PP_Fcu_Cps_TxSignal_Aeb.Cps_SignalPhyData_FC_AEBTargetmode
              dsp_Cps_SignalPhyData_FC_AEB9: accessed-variable=PP_Fcu_Cps_TxSignal_Aeb.Cps_SignalPhyData_FC_AEBTextInfo
              dsp_Cps_SignalPhyData_FC_AWB: accessed-variable=PP_Fcu_Cps_TxSignal_Aeb.Cps_SignalPhyData_FC_AWBlevel
              dsp_Cps_SignalPhyData_FC_AWB0: accessed-variable=PP_Fcu_Cps_TxSignal_Aeb.Cps_SignalPhyData_FC_AWBActive
              dsp_Cps_SignalPhyData_FC_ELK: accessed-variable=PP_Fcu_Cps_TxSignal_Lcf.Cps_SignalPhyData_FC_ELKMode
              dsp_Cps_SignalPhyData_FC_ELK0: accessed-variable=PP_Fcu_Cps_TxSignal_Lcf.Cps_SignalPhyData_FC_ELKInterventionMode
              dsp_Cps_SignalPhyData_FC_ELK1: accessed-variable=PP_Fcu_Cps_TxSignal_Lcf.Cps_SignalPhyData_FC_ELKEnableStatus
              dsp_Cps_SignalPhyData_FC_FCW: accessed-variable=PP_Fcu_Cps_TxSignal_Aeb.Cps_SignalPhyData_FC_FCWStatus
              dsp_Cps_SignalPhyData_FC_FCW0: accessed-variable=PP_Fcu_Cps_TxSignal_Aeb.Cps_SignalPhyData_FC_FCWActive
              dsp_Cps_SignalPhyData_FC_FCW1: accessed-variable=PP_Fcu_Cps_TxSignal_Aeb.Cps_SignalPhyData_FC_FCWPreWarning
              dsp_Cps_SignalPhyData_FC_FCW2: accessed-variable=PP_Fcu_Cps_TxSignal_Aeb.Cps_SignalPhyData_FC_FCWLatentWarning
              dsp_Cps_SignalPhyData_FC_FCW3: accessed-variable=PP_Fcu_Cps_TxSignal_Aeb.Cps_SignalPhyData_FC_FCWSettingStatus
              dsp_Cps_SignalPhyData_FC_HMA: accessed-variable=PP_Fcu_Cps_TxSignal_Hla.Cps_SignalPhyData_FC_HMALightDistribution
              dsp_Cps_SignalPhyData_FC_HMA0: accessed-variable=PP_Fcu_Cps_TxSignal_Hla.Cps_SignalPhyData_FC_HMAEnableStatus
              dsp_Cps_SignalPhyData_FC_HMA1: accessed-variable=PP_Fcu_Cps_TxSignal_Hla.Cps_SignalPhyData_FC_HMAStatus
              dsp_Cps_SignalPhyData_FC_Hos: accessed-variable=PP_Fcu_Cps_TxSignal_Lcf.Cps_SignalPhyData_FC_HostLaneLeftStatus
              dsp_Cps_SignalPhyData_FC_Hos0: accessed-variable=PP_Fcu_Cps_TxSignal_Acc.Cps_SignalPhyData_FC_ACC_temp
              dsp_Cps_SignalPhyData_FC_Hos1: accessed-variable=PP_Fcu_Cps_TxSignal_Lcf.Cps_SignalPhyData_FC_HostLaneRightStatus
              dsp_Cps_SignalPhyData_FC_LAS: accessed-variable=PP_Fcu_Cps_TxSignal_Lcf.Cps_SignalPhyData_FC_LASModeSelectionStatus
              dsp_Cps_SignalPhyData_FC_LAS0: accessed-variable=PP_Fcu_Cps_TxSignal_Lcf.Cps_SignalPhyData_FC_LASWarningModeSelectionSts
              dsp_Cps_SignalPhyData_FC_LDW: accessed-variable=PP_Fcu_Cps_TxSignal_Lcf.Cps_SignalPhyData_FC_LDWStatus
              dsp_Cps_SignalPhyData_FC_LDW0: accessed-variable=PP_Fcu_Cps_TxSignal_Lcf.Cps_SignalPhyData_FC_LDWVibrationWarningReq
              dsp_Cps_SignalPhyData_FC_LDW1: accessed-variable=PP_Fcu_Cps_TxSignal_Lcf.Cps_SignalPhyData_FC_LDWShakeLevStatus
              dsp_Cps_SignalPhyData_FC_LKA: accessed-variable=PP_Fcu_Cps_TxSignal_Lcf.Cps_SignalPhyData_FC_LKAStatus
              dsp_Cps_SignalPhyData_FC_LKA0: accessed-variable=PP_Fcu_Cps_TxSignal_Lcf.Cps_SignalPhyData_FC_LKATakeoverReq
              dsp_Cps_SignalPhyData_FC_LLa: accessed-variable=PP_Fcu_Cps_TxSignal_Aeb.Cps_SignalPhyData_FC_LLaneDistanceFus
              dsp_Cps_SignalPhyData_FC_LLa0: accessed-variable=PP_Fcu_Cps_TxSignal_Aeb.Cps_SignalPhyData_FC_LLaneMarkerType
              dsp_Cps_SignalPhyData_FC_Lat: accessed-variable=PP_Fcu_Cps_TxSignal_Lcf.Cps_SignalPhyData_FC_LatAngReqActive
              dsp_Cps_SignalPhyData_FC_Lat0: accessed-variable=PP_Fcu_Cps_TxSignal_Lcf.Cps_SignalPhyData_FC_LatAngReq
              dsp_Cps_SignalPhyData_FC_Mot: accessed-variable=PP_Fcu_Cps_TxSignal_Lcf.Cps_SignalPhyData_FC_MotorTorqueMaxLimitRequest
              dsp_Cps_SignalPhyData_FC_Mot0: accessed-variable=PP_Fcu_Cps_TxSignal_Lcf.Cps_SignalPhyData_FC_MotorTorqueMinLimitRequest
              dsp_Cps_SignalPhyData_FC_OBJ: accessed-variable=PP_Fcu_Cps_TxSignal_Aeb.Cps_SignalPhyData_FC_OBJ_AEB_ID
              dsp_Cps_SignalPhyData_FC_Pre: accessed-variable=PP_Fcu_Cps_TxSignal_Aeb.Cps_SignalPhyData_FC_PrefillActive
              dsp_Cps_SignalPhyData_FC_RLa: accessed-variable=PP_Fcu_Cps_TxSignal_Aeb.Cps_SignalPhyData_FC_RLaneDistanceFus
              dsp_Cps_SignalPhyData_FC_RLa0: accessed-variable=PP_Fcu_Cps_TxSignal_Aeb.Cps_SignalPhyData_FC_RLaneMarkerType
              dsp_Cps_SignalPhyData_FC_Voi: accessed-variable=PP_Fcu_Cps_TxSignal_Lcf.Cps_SignalPhyData_FC_Voiceinfo
              dsp_DE_FC_AEBStatus: accessed-variable=PP_Fcu_SRI_FC_AEBStatus.DE_FC_AEBStatus
              dsp_DE_FC_ELKMode: accessed-variable=PP_Fcu_SRI_FC_ELKModeStatus.DE_FC_ELKMode
              dsp_DE_FC_FCWStatus: accessed-variable=PP_Fcu_SRI_FC_FCWStatus.DE_FC_FCWStatus
              dsp_DE_FC_HMAStatus: accessed-variable=PP_Fcu_SRI_FC_HMAStatus.DE_FC_HMAStatus
              dsp_DE_FC_LDWStatus: accessed-variable=PP_Fcu_SRI_FC_LDWStatus.DE_FC_LDWStatus
              dsp_DE_FC_LKAStatus: accessed-variable=PP_Fcu_SRI_FC_LKAStatus.DE_FC_LKAStatus
              dsp_DimInputCustomData: accessed-variable=PP_Fcu_DimInputCustomData.DimInputCustomData
              dsp_DimInputGenericData: accessed-variable=PP_Fcu_DimInputGenericData.DimInputGenericData
              dsp_FctCtrlData: accessed-variable=PP_Fcu_FctCtrlData.FctCtrlData
              dsp_HeadInputCustomData: accessed-variable=PP_Fcu_HeadInputCustomData.HeadInputCustomData
              dsp_HeadInputGenericData: accessed-variable=PP_Fcu_HeadInputGenericData.HeadInputGenericData
              dsp_Hla_InputSignals_t: accessed-variable=PP_Fcu_HlaInputData.Hla_InputSignals_t
              dsp_LcfGenericInputData: accessed-variable=PP_Fcu_LcfGenericInputData.LcfGenericInputData
              dsp_VehPar: accessed-variable=PP_Fcu_VehPar.VehPar
              dsp_VehSig: accessed-variable=PP_Fcu_VehSig.VehSig
          11 x sync call, all with timeout=0.0:
            scp_Cdm_GetErrorStatus: operation=RP_Cdm_FcuBlockOp.Cdm_GetErrorStatus
            scp_Cdm_ReadBlock: operation=RP_Cdm_FcuBlockOp.Cdm_ReadBlock
            scp_Cdm_WriteBlock: operation=RP_Cdm_FcuBlockOp.Cdm_WriteBlock
            scp_GetErrorStatus: operation=RP_Nvm_HMISwitchStatus.GetErrorStatus
            scp_HostLane_Left_flag_Read: operation=RP_Sdc_SendInterface_Perception.HostLane_Left_flag_Read
            scp_HostLane_Right_flag_Read: operation=RP_Sdc_SendInterface_Perception.HostLane_Right_flag_Read
            scp_J3_PerceptionData_Read: operation=RP_Sdc_SendInterface_Perception.J3_PerceptionData_Read
            scp_Len_to_Left_Lane_Read: operation=RP_Sdc_SendInterface_Perception.Len_to_Left_Lane_Read
            scp_Len_to_Right_Lane_Read: operation=RP_Sdc_SendInterface_Perception.Len_to_Right_Lane_Read
            scp_SetRamBlockStatus: operation=RP_Nvm_HMISwitchStatus.SetRamBlockStatus
            scp_WriteBlock: operation=RP_Nvm_HMISwitchStatus.WriteBlock
        Fcu_MainFunction_Rx
          data-receive-point-by-arguments:
            4 x access:
              drparg_GenObjectList: accessed-variable=RP_Sdc_Cem_GenObjectList.GenObjectList
              drparg_HeadOutputCustomData: accessed-variable=RP_FctAdapter_HeadOutputCustomData.HeadOutputCustomData
              drparg_LcfSenGenericOutputDa: accessed-variable=RP_LcfAdapter_LcfSenGenericOutputData.LcfSenGenericOutputData
              drparg_LcfVehGenericOutputDa: accessed-variable=RP_LcfAdapter_LcfVehGenericOutputData.LcfVehGenricOutputData
          data-send-points:
            9 x access:
              dsp_BaseCtrlData: accessed-variable=PP_Fcu_BaseCtrlData.BaseCtrlData
              dsp_DimInputCustomData: accessed-variable=PP_Fcu_DimInputCustomData.DimInputCustomData
              dsp_DimInputGenericData: accessed-variable=PP_Fcu_DimInputGenericData.DimInputGenericData
              dsp_FctCtrlData: accessed-variable=PP_Fcu_FctCtrlData.FctCtrlData
              dsp_HeadInputCustomData: accessed-variable=PP_Fcu_HeadInputCustomData.HeadInputCustomData
              dsp_HeadInputGenericData: accessed-variable=PP_Fcu_HeadInputGenericData.HeadInputGenericData
              dsp_LcfGenericInputData: accessed-variable=PP_Fcu_LcfGenericInputData.LcfGenericInputData
              dsp_VehPar: accessed-variable=PP_Fcu_VehPar.VehPar
              dsp_VehSig: accessed-variable=PP_Fcu_VehSig.VehSig
        Fcu_MainFunction_Tx
          data-receive-point-by-arguments:
            4 x access:
              drparg_GenObjectList: accessed-variable=RP_Sdc_Cem_GenObjectList.GenObjectList
              drparg_HeadOutputCustomData: accessed-variable=RP_FctAdapter_HeadOutputCustomData.HeadOutputCustomData
              drparg_LcfSenGenericOutputDa: accessed-variable=RP_LcfAdapter_LcfSenGenericOutputData.LcfSenGenericOutputData
              drparg_LcfVehGenericOutputDa: accessed-variable=RP_LcfAdapter_LcfVehGenericOutputData.LcfVehGenricOutputData
          data-send-points:
            9 x access:
              dsp_BaseCtrlData: accessed-variable=PP_Fcu_BaseCtrlData.BaseCtrlData
              dsp_DimInputCustomData: accessed-variable=PP_Fcu_DimInputCustomData.DimInputCustomData
              dsp_DimInputGenericData: accessed-variable=PP_Fcu_DimInputGenericData.DimInputGenericData
              dsp_FctCtrlData: accessed-variable=PP_Fcu_FctCtrlData.FctCtrlData
              dsp_HeadInputCustomData: accessed-variable=PP_Fcu_HeadInputCustomData.HeadInputCustomData
              dsp_HeadInputGenericData: accessed-variable=PP_Fcu_HeadInputGenericData.HeadInputGenericData
              dsp_LcfGenericInputData: accessed-variable=PP_Fcu_LcfGenericInputData.LcfGenericInputData
              dsp_VehPar: accessed-variable=PP_Fcu_VehPar.VehPar
              dsp_VehSig: accessed-variable=PP_Fcu_VehSig.VehSig
  swc implementation FcuImpl: programming-language=C, sw-version=0.0.1, vendor-id=0, behavior=Fcu_IB
    code-descriptors:
      code CodeGen: artifact-descriptors=[{short-label=SWSRC, category=SWSRC}, {short-label=SWHDR, category=SWHDR}]
    resource consumption Resource
      memory section CODE: sw-addrmethod=CODE
      memory section VAR_UNSPECIFIED: sw-addrmethod=VAR
